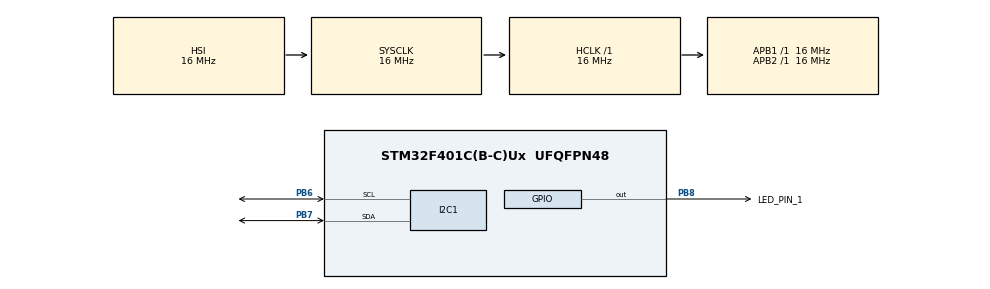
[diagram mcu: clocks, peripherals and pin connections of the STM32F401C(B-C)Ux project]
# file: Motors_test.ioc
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Mcu.Family=STM32F4
Mcu.Name=STM32F401C(B-C)Ux
Mcu.Package=UFQFPN48
NVIC.PriorityGroup=NVIC_PRIORITYGROUP_4
PB6.Mode=I2C
PB6.Signal=I2C1_SCL
PB7.Mode=I2C
PB7.Signal=I2C1_SDA
PB8.GPIO_Label=LED_PIN_1
PB8.Signal=GPIO_Output
PH0\ -\ OSC_IN.Mode=HSE-External-Oscillator
PH0\ -\ OSC_IN.Signal=RCC_OSC_IN
PH1\ -\ OSC_OUT.Mode=HSE-External-Oscillator
PH1\ -\ OSC_OUT.Signal=RCC_OSC_OUT
ProjectManager.HeapSize=0x400
ProjectManager.StackSize=0x800
ProjectManager.TargetToolchain=STM32CubeIDE
RCC.AHBFreq_Value=16000000
RCC.APB1Freq_Value=16000000
RCC.APB2Freq_Value=16000000
RCC.CortexFreq_Value=16000000
RCC.HSE_VALUE=25000000
RCC.HSI_VALUE=16000000
RCC.LSE_VALUE=32768
RCC.SYSCLKFreq_VALUE=16000000
RCC.VCOOutputFreq_Value=192000000
board=custom

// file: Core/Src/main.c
/* USER CODE BEGIN Header */
/**
  ******************************************************************************
  * @file           : main.c
  * @brief          : Main program body
  ******************************************************************************
  * @attention
  *
  * Copyright (c) 2026 STMicroelectronics.
  * All rights reserved.
  *
  * This software is licensed under terms that can be found in the LICENSE file
  * in the root directory of this software component.
  * If no LICENSE file comes with this software, it is provided AS-IS.
  *
  ******************************************************************************
  */
/* USER CODE END Header */
#include "main.h"
#include "i2c.h"
#include "gpio.h"

/* USER CODE BEGIN Includes */
#include "motor_control.h"
#include "pca9685.h"
/* USER CODE END Includes */

void SystemClock_Config(void);
/* USER CODE BEGIN PFP */
Motor_HandleTypeDef motorA, motorB, motorC, motorD, motorE, motorF;
/* USER CODE END PFP */

int main(void)
{

  /* MCU Configuration--------------------------------------------------------*/

  /* Reset of all peripherals, Initializes the Flash interface and the Systick. */
  HAL_Init();

  /* Configure the system clock */
  SystemClock_Config();

  /* Initialize all configured peripherals */
  MX_GPIO_Init();
  MX_I2C1_Init();
  /* USER CODE BEGIN 2 */
  HAL_GPIO_WritePin(LED_PIN_1_GPIO_Port, LED_PIN_1_Pin, 1);
    PCA9685_Init(50);
    Motor_Init(&motorD, 0, 1);
    Motor_Init(&motorC, 2, 3);
    Motor_Init(&motorB, 4, 5);
    Motor_Init(&motorA, 6, 7);
    Motor_Init(&motorF, 11, 12);
    Motor_Init(&motorE, 13, 14);
  /* USER CODE END 2 */

  /* Infinite loop */
  /* USER CODE BEGIN WHILE */
  while (1)
  {
	  /*Motor_SetSpeed(&motorE, -100);
	  	  HAL_Delay(750);
	  	  //Motor_SetSpeed(&motorE, -100);
	  	  //HAL_Delay(250);
	  	  Motor_Brake(&motorE);
	  	  Motor_Coast(&motorE);
	  	  break;*/
	  	  Motor_SetSpeed(&motorF, 100);
	  	  HAL_Delay(250);
	  	  Motor_SetSpeed(&motorF, -100);
	  	  HAL_Delay(250);
	  	  Motor_Brake(&motorF);
	  	  Motor_Coast(&motorF);
	  	  /*Motor_SetSpeed(&motorC, 100);
	  	  HAL_Delay(250);
	  	  Motor_SetSpeed(&motorC, -100);
	  	  HAL_Delay(250);
	  	  Motor_Brake(&motorC);
	  	  Motor_Coast(&motorC);
	  	  Motor_SetSpeed(&motorD, 100);
	  	  HAL_Delay(250);
	  	  Motor_SetSpeed(&motorD, -100);
	  	  HAL_Delay(250);
	  	  Motor_Brake(&motorD);
	  	  Motor_Coast(&motorD);*/
    /* USER CODE END WHILE */

  }
}

void SystemClock_Config(void)
{
  RCC_OscInitTypeDef RCC_OscInitStruct = {0};
  RCC_ClkInitTypeDef RCC_ClkInitStruct = {0};

  /** Configure the main internal regulator output voltage
  */
  __HAL_RCC_PWR_CLK_ENABLE();
  __HAL_PWR_VOLTAGESCALING_CONFIG(PWR_REGULATOR_VOLTAGE_SCALE2);

  /** Initializes the RCC Oscillators according to the specified parameters
  * in the RCC_OscInitTypeDef structure.
  */
  RCC_OscInitStruct.OscillatorType = RCC_OSCILLATORTYPE_HSI;
  RCC_OscInitStruct.HSIState = RCC_HSI_ON;
  RCC_OscInitStruct.HSICalibrationValue = RCC_HSICALIBRATION_DEFAULT;
  RCC_OscInitStruct.PLL.PLLState = RCC_PLL_NONE;
  if (HAL_RCC_OscConfig(&RCC_OscInitStruct) != HAL_OK)
  {
    Error_Handler();
  }

  /** Initializes the CPU, AHB and APB buses clocks
  */
  RCC_ClkInitStruct.ClockType = RCC_CLOCKTYPE_HCLK|RCC_CLOCKTYPE_SYSCLK
                              |RCC_CLOCKTYPE_PCLK1|RCC_CLOCKTYPE_PCLK2;
  RCC_ClkInitStruct.SYSCLKSource = RCC_SYSCLKSOURCE_HSI;
  RCC_ClkInitStruct.AHBCLKDivider = RCC_SYSCLK_DIV1;
  RCC_ClkInitStruct.APB1CLKDivider = RCC_HCLK_DIV1;
  RCC_ClkInitStruct.APB2CLKDivider = RCC_HCLK_DIV1;

  if (HAL_RCC_ClockConfig(&RCC_ClkInitStruct, FLASH_LATENCY_0) != HAL_OK)
  {
    Error_Handler();
  }
}

void Error_Handler(void)
{
  __disable_irq();
  while (1)
  {
  }
}
